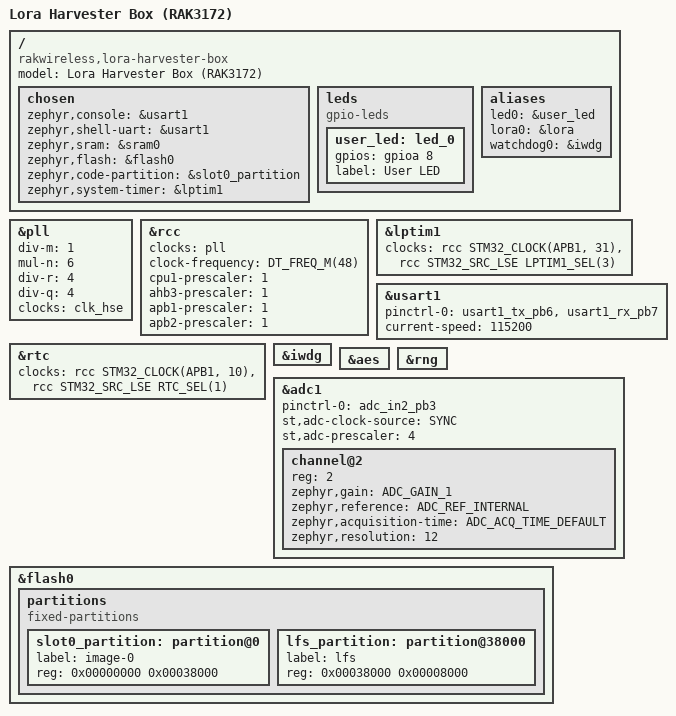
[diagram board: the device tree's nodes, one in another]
/*
 * Copyright (c) 2026 ZephCore
 * SPDX-License-Identifier: MIT
 * Lora Harvester Box (RAK3172 / STM32WLE5CC) carrier. Reuses the upstream
 * RAK3172 radio descriptor (arm/rakwireless/rak3172.dtsi).
 */

/dts-v1/;
#include <arm/rakwireless/rak3172.dtsi>
#include <zephyr/dt-bindings/adc/adc.h>

/ {
	model = "Lora Harvester Box (RAK3172)";
	compatible = "rakwireless,lora-harvester-box";

	chosen {
		zephyr,console = &usart1;
		zephyr,shell-uart = &usart1;
		zephyr,sram = &sram0;
		zephyr,flash = &flash0;
		zephyr,code-partition = &slot0_partition;
		zephyr,system-timer = &lptim1;
	};

	leds {
		compatible = "gpio-leds";

		user_led: led_0 {
			gpios = <&gpioa 8 GPIO_ACTIVE_HIGH>;
			label = "User LED";
		};
	};

	aliases {
		led0 = &user_led;
		lora0 = &lora;
		watchdog0 = &iwdg;
	};
};

/* 48 MHz from the 32 MHz HSE via PLL. */
&pll {
	div-m = <1>;
	mul-n = <6>;
	div-r = <4>;
	div-q = <4>;
	clocks = <&clk_hse>;
	status = "okay";
};

&rcc {
	clocks = <&pll>;
	clock-frequency = <DT_FREQ_M(48)>;
	cpu1-prescaler = <1>;
	ahb3-prescaler = <1>;
	apb1-prescaler = <1>;
	apb2-prescaler = <1>;
};

&lptim1 {
	clocks = <&rcc STM32_CLOCK(APB1, 31)>,
		 <&rcc STM32_SRC_LSE LPTIM1_SEL(3)>;
	status = "okay";
};

&usart1 {
	pinctrl-0 = <&usart1_tx_pb6 &usart1_rx_pb7>;
	pinctrl-names = "default";
	current-speed = <115200>;
	status = "okay";
};

&rtc {
	clocks = <&rcc STM32_CLOCK(APB1, 10)>,
		 <&rcc STM32_SRC_LSE RTC_SEL(1)>;
	status = "okay";
};

&iwdg {
	status = "okay";
};

&aes {
	status = "okay";
};

&rng {
	status = "okay";
};

&adc1 {
	pinctrl-0 = <&adc_in2_pb3>;
	pinctrl-names = "default";
	st,adc-clock-source = "SYNC";
	st,adc-prescaler = <4>;
	status = "okay";
	#address-cells = <1>;
	#size-cells = <0>;

	channel@2 {
		reg = <2>;
		zephyr,gain = "ADC_GAIN_1";
		zephyr,reference = "ADC_REF_INTERNAL";
		zephyr,acquisition-time = <ADC_ACQ_TIME_DEFAULT>;
		zephyr,resolution = <12>;
	};
};

/* No MCUboot: 224 KB app + 32 KB LittleFS. */
&flash0 {
	partitions {
		compatible = "fixed-partitions";
		#address-cells = <1>;
		#size-cells = <1>;

		slot0_partition: partition@0 {
			label = "image-0";
			reg = <0x00000000 0x00038000>;
		};

		lfs_partition: partition@38000 {
			label = "lfs";
			reg = <0x00038000 0x00008000>;
		};
	};
};
